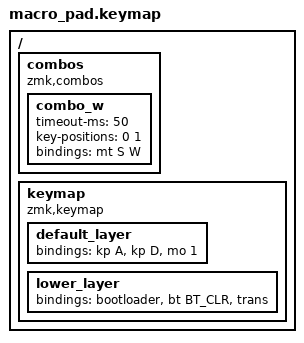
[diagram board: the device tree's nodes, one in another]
#include <behaviors.dtsi>
#include <dt-bindings/zmk/keys.h>
#include <dt-bindings/zmk/bt.h>

/ {
    combos {
        compatible = "zmk,combos";
        combo_w {
            timeout-ms = <50>;
            key-positions = <0 1>;
            bindings = <&mt S W>;
        };
    };
    keymap {
        compatible = "zmk,keymap";

        default_layer {
           bindings = <
               &kp A    &kp D    &mo 1
            >;
        };

        lower_layer {
           bindings = <
               &bootloader    &bt BT_CLR    &trans
            >;
        };

    };
};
